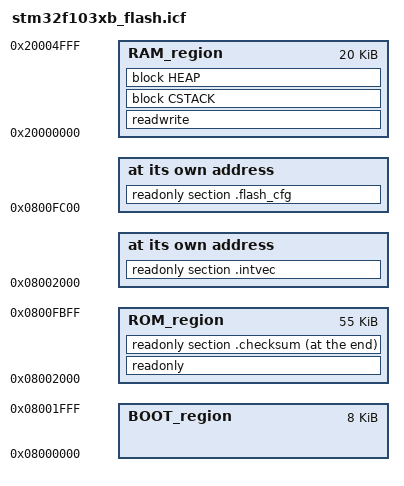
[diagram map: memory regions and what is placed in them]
/*###ICF### Section handled by ICF editor, don't touch! ****/
/*-Editor annotation file-*/
/* IcfEditorFile="$TOOLKIT_DIR$\config\ide\IcfEditor\cortex_v1_0.xml" */
/*-Specials-*/
define symbol __ICFEDIT_intvec_start__ = 0x08002000;
/*-Memory Regions-*/
define symbol __ICFEDIT_region_ROM_start__   = 0x08002000 ;
define symbol __ICFEDIT_region_ROM_end__     = 0x0800FBFF;
define symbol __ICFEDIT_region_RAM_start__   = 0x20000000;
define symbol __ICFEDIT_region_RAM_end__     = 0x20004FFF;
/*-Sizes-*/
define symbol __ICFEDIT_size_cstack__ = 0x400;
define symbol __ICFEDIT_size_heap__   = 0x200;
/**** End of ICF editor section. ###ICF###*/



define symbol __BOOTLOADER_START__ = 0x08000000;
define symbol __BOOTLOADER_END__   = 0x08001FFF;

define symbol __FLASH_CFG_START__ = 0x0800FC00;
define symbol __FLASH_CFG_END__   = 0x0800FFFF;

define memory mem with size = 4G;
define region BOOT_region  = mem:[from __BOOTLOADER_START__           to __BOOTLOADER_END__];
define region ROM_region   = mem:[from __ICFEDIT_region_ROM_start__   to __ICFEDIT_region_ROM_end__];
define region RAM_region   = mem:[from __ICFEDIT_region_RAM_start__   to __ICFEDIT_region_RAM_end__];

define block CSTACK    with alignment = 8, size = __ICFEDIT_size_cstack__   { };
define block HEAP      with alignment = 8, size = __ICFEDIT_size_heap__     { };

initialize by copy { readwrite };
do not initialize  { section .noinit };

place at address mem:__ICFEDIT_intvec_start__ { readonly section .intvec };

keep { section .flash_cfg };
place in ROM_region   { readonly };
place at address mem:__FLASH_CFG_START__ { readonly section .flash_cfg };
place in RAM_region   { readwrite,
                        block CSTACK, block HEAP };
place at end of ROM_region { readonly section .checksum };
